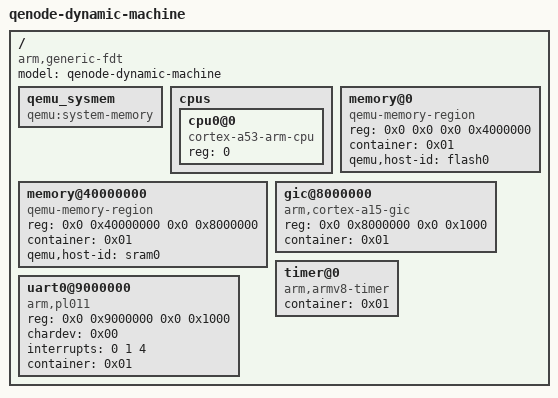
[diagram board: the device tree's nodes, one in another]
/dts-v1/;

/ {
    model = "qenode-dynamic-machine";
    compatible = "arm,generic-fdt";
    #address-cells = <2>;
    #size-cells = <2>;

    qemu_sysmem: qemu_sysmem {
        compatible = "qemu:system-memory";
        phandle = <0x01>;
    };

    cpus {
        #address-cells = <1>;
        #size-cells = <0>;
        cpu0@0 {
            device_type = "cpu";
            compatible = "cortex-a53-arm-cpu";
            reg = <0>;
        };
    };

    memory@0 {
        device_type = "memory";
        compatible = "qemu-memory-region";
        reg = <0x0 0x0 0x0 0x4000000>;
        container = <0x01>;
        qemu,host-id = "flash0";
    };
    memory@40000000 {
        device_type = "memory";
        compatible = "qemu-memory-region";
        reg = <0x0 0x40000000 0x0 0x8000000>;
        container = <0x01>;
        qemu,host-id = "sram0";
    };
    gic@8000000 {
        compatible = "arm,cortex-a15-gic";
        reg = <0x0 0x8000000 0x0 0x1000>;
        container = <0x01>;
    };
    timer@0 {
        compatible = "arm,armv8-timer";
        container = <0x01>;
    };
    uart0@9000000 {
        compatible = "arm,pl011";
        reg = <0x0 0x9000000 0x0 0x1000>;
        chardev = <0x00>;
        interrupts = <0 1 4>;
        container = <0x01>;
    };
};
